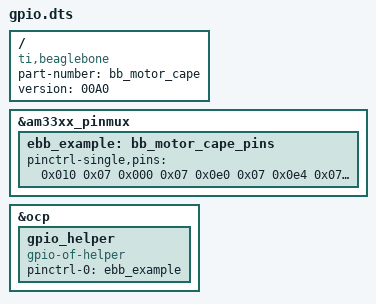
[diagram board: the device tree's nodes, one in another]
/*  
* Copyright (C) 2012 Texas Instruments Incorporated - http://www.ti.com/
*
* This program is free software; you can redistribute it and/or modify
* it under the terms of the GNU General Purpose License Version 2 as
* published by the Free Software Foundation
*
* Original from: github.com/jadonk/validation-scripts/blob/master/test-capemgr/ 
*
* Modified by Derek Molloy for the example on www.derekmolloy.ie
* that maps GPIO pins for the example
*/

/dts-v1/;
/plugin/;

/{
       compatible = "ti,beaglebone", "ti,beaglebone-black";
	part-number = "bb_motor_cape";
        version = "00A0";

       fragment@0 {
             target = <&am33xx_pinmux>;
            
             __overlay__ {
                  ebb_example: bb_motor_cape_pins {
			pinctrl-single,pins = <
					0x010 0x07	/* P8_23 muxRegOffset, OUTPUT | MODE7 */
					0x000 0x07	/* P8_25 muxRegOffset, OUTPUT | MODE7 */
					0x0e0 0x07	/* P8_27 muxRegOffset, OUTPUT | MODE7 */
					0x0e4 0x07	/* P8_29 muxRegOffset, OUTPUT | MODE7 */
					0x0d8 0x07	/* P8_31 muxRegOffset, OUTPUT | MODE7 */
					0x0d4 0x07	/* P8_33 muxRegOffset, OUTPUT | MODE7 */
					0x0d0 0x07	/* P8_35 muxRegOffset, OUTPUT | MODE7 */
					0x018 0x07	/* P8_3 muxRegOffset, OUTPUT | MODE7 */
					0x008 0x07	/* P8_5 muxRegOffset, OUTPUT | MODE7 */
  
                               /* OUTPUT  GPIO(mode7) 0x07 pulldown, 0x17 pullup, 0x?f no pullup/down */
			       /* INPUT   GPIO(mode7) 0x27 pulldown, 0x37 pullup, 0x?f no pullup/down */
			>;
		  };
             };
       };

       fragment@1 {
		target = <&ocp>;
		__overlay__ {
			gpio_helper {
				compatible = "gpio-of-helper";
				status = "okay";
				pinctrl-names = "default";
				pinctrl-0 = <&ebb_example>;
			};
		};
	};
};
